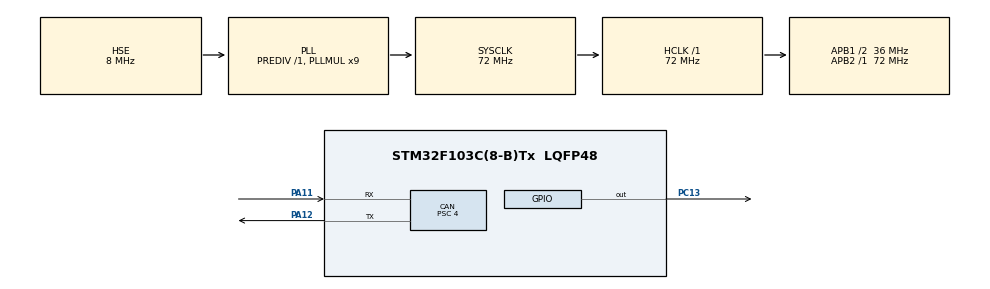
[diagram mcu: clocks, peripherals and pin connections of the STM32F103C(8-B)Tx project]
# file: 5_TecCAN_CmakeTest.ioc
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CAN.ABOM=ENABLE
CAN.BS1=CAN_BS1_14TQ
CAN.BS2=CAN_BS2_3TQ
CAN.CalculateBaudRate=500000
CAN.CalculateTimeBit=2000
CAN.CalculateTimeQuantum=111.11111111111111
CAN.Mode=CAN_MODE_NORMAL
CAN.NART=ENABLE
CAN.Prescaler=4
CAN.SJW=CAN_SJW_2TQ
CAN.TXFP=ENABLE
Mcu.Family=STM32F1
Mcu.Name=STM32F103C(8-B)Tx
Mcu.Package=LQFP48
NVIC.PriorityGroup=NVIC_PRIORITYGROUP_4
NVIC.USB_LP_CAN1_RX0_IRQn=true\:0\:0\:false\:false\:true\:true\:true\:true
PA11.Mode=CAN_Activate
PA11.Signal=CAN_RX
PA12.Mode=CAN_Activate
PA12.Signal=CAN_TX
PA13.Mode=Serial_Wire
PA13.Signal=SYS_JTMS-SWDIO
PA14.Mode=Serial_Wire
PA14.Signal=SYS_JTCK-SWCLK
PC13-TAMPER-RTC.PinState=GPIO_PIN_SET
PC13-TAMPER-RTC.Signal=GPIO_Output
PD0-OSC_IN.Mode=HSE-External-Oscillator
PD0-OSC_IN.Signal=RCC_OSC_IN
PD1-OSC_OUT.Mode=HSE-External-Oscillator
PD1-OSC_OUT.Signal=RCC_OSC_OUT
ProjectManager.HeapSize=0x200
ProjectManager.StackSize=0x800
ProjectManager.TargetToolchain=CMake
RCC.AHBFreq_Value=72000000
RCC.APB1CLKDivider=RCC_HCLK_DIV2
RCC.APB1Freq_Value=36000000
RCC.APB1TimFreq_Value=72000000
RCC.APB2Freq_Value=72000000
RCC.APB2TimFreq_Value=72000000
RCC.EnbaleCSS=true
RCC.HCLKFreq_Value=72000000
RCC.PLLMUL=RCC_PLL_MUL9
RCC.PLLSourceVirtual=RCC_PLLSOURCE_HSE
RCC.SYSCLKFreq_VALUE=72000000
RCC.SYSCLKSource=RCC_SYSCLKSOURCE_PLLCLK
RCC.USBFreq_Value=72000000
board=custom

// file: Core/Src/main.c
/* USER CODE BEGIN Header */
/**
  ******************************************************************************
  * @file           : main.c
  * @brief          : Main program body
  ******************************************************************************
  * @attention
  *
  * Copyright (c) 2025 STMicroelectronics.
  * All rights reserved.
  *
  * This software is licensed under terms that can be found in the LICENSE file
  * in the root directory of this software component.
  * If no LICENSE file comes with this software, it is provided AS-IS.
  *
  ******************************************************************************
  */
/* USER CODE END Header */
#include "main.h"
#include "can.h"
#include "gpio.h"

/* USER CODE BEGIN PV */

CAN_TxHeaderTypeDef TxHeader; // 发送句柄
CAN_RxHeaderTypeDef RxHeader; // 接收句柄
uint8_t TxData[8];
uint8_t RxData[8];
uint32_t TxMailbox;

/* USER CODE END PV */

void SystemClock_Config(void);

int main(void)
{

  /* MCU Configuration--------------------------------------------------------*/

  /* Reset of all peripherals, Initializes the Flash interface and the Systick. */
  HAL_Init();

  /* Configure the system clock */
  SystemClock_Config();

  /* Initialize all configured peripherals */
  MX_GPIO_Init();
  MX_CAN_Init();
  /* USER CODE BEGIN 2 */

  CAN_FilterTypeDef sFilterConfig;

sFilterConfig.FilterBank = 0;
sFilterConfig.FilterMode = CAN_FILTERMODE_IDMASK;
sFilterConfig.FilterScale = CAN_FILTERSCALE_32BIT;
sFilterConfig.FilterIdHigh = 0x0000;
sFilterConfig.FilterIdLow = 0x0000;
sFilterConfig.FilterMaskIdHigh = 0x0000;
sFilterConfig.FilterMaskIdLow = 0x0000; // 0表示允许所有ID通过
sFilterConfig.FilterFIFOAssignment = CAN_RX_FIFO0;
sFilterConfig.FilterActivation = ENABLE;
sFilterConfig.SlaveStartFilterBank = 0;

if (HAL_CAN_ConfigFilter(&hcan, &sFilterConfig) != HAL_OK) {
    Error_Handler();
}

HAL_CAN_Start(&hcan); // 启动CAN
HAL_CAN_ActivateNotification(&hcan, CAN_IT_RX_FIFO0_MSG_PENDING); // 开启中断通知

  /* USER CODE END 2 */

  /* Infinite loop */
  /* USER CODE BEGIN WHILE */

  TxHeader.StdId = 0x123;
TxHeader.RTR = CAN_RTR_DATA;
TxHeader.IDE = CAN_ID_STD;
TxHeader.DLC = 8;
TxData[0] = 0xAA; // 测试数据

  while (1)
  {
    if (HAL_CAN_GetTxMailboxesFreeLevel(&hcan) > 0)
    {
        HAL_CAN_AddTxMessage(&hcan, &TxHeader, TxData, &TxMailbox);
    }
    HAL_Delay(100);
    // HAL_CAN_AddTxMessage(&hcan, &TxHeader, TxData, &TxMailbox);
    // // HAL_GPIO_TogglePin(GPIOC, GPIO_PIN_13); // 翻转电平（用于观察）
    // HAL_Delay(500); // 每半秒发一次

    /* USER CODE END WHILE */

  }
}

void SystemClock_Config(void)
{
  RCC_OscInitTypeDef RCC_OscInitStruct = {0};
  RCC_ClkInitTypeDef RCC_ClkInitStruct = {0};

  /** Initializes the RCC Oscillators according to the specified parameters
  * in the RCC_OscInitTypeDef structure.
  */
  RCC_OscInitStruct.OscillatorType = RCC_OSCILLATORTYPE_HSE;
  RCC_OscInitStruct.HSEState = RCC_HSE_ON;
  RCC_OscInitStruct.HSEPredivValue = RCC_HSE_PREDIV_DIV1;
  RCC_OscInitStruct.HSIState = RCC_HSI_ON;
  RCC_OscInitStruct.PLL.PLLState = RCC_PLL_ON;
  RCC_OscInitStruct.PLL.PLLSource = RCC_PLLSOURCE_HSE;
  RCC_OscInitStruct.PLL.PLLMUL = RCC_PLL_MUL9;
  if (HAL_RCC_OscConfig(&RCC_OscInitStruct) != HAL_OK)
  {
    Error_Handler();
  }

  /** Initializes the CPU, AHB and APB buses clocks
  */
  RCC_ClkInitStruct.ClockType = RCC_CLOCKTYPE_HCLK|RCC_CLOCKTYPE_SYSCLK
                              |RCC_CLOCKTYPE_PCLK1|RCC_CLOCKTYPE_PCLK2;
  RCC_ClkInitStruct.SYSCLKSource = RCC_SYSCLKSOURCE_PLLCLK;
  RCC_ClkInitStruct.AHBCLKDivider = RCC_SYSCLK_DIV1;
  RCC_ClkInitStruct.APB1CLKDivider = RCC_HCLK_DIV2;
  RCC_ClkInitStruct.APB2CLKDivider = RCC_HCLK_DIV1;

  if (HAL_RCC_ClockConfig(&RCC_ClkInitStruct, FLASH_LATENCY_2) != HAL_OK)
  {
    Error_Handler();
  }

  /** Enables the Clock Security System
  */
  HAL_RCC_EnableCSS();
}

/* USER CODE BEGIN 4 */

void HAL_CAN_RxFifo0MsgPendingCallback(CAN_HandleTypeDef *hcan) {
    if (HAL_CAN_GetRxMessage(hcan, CAN_RX_FIFO0, &RxHeader, RxData) == HAL_OK) {
        // 如果接收到 ID 为 0x123 的消息，翻转电平（用于观察）
        // if (RxHeader.StdId == 0x123) {
        //     HAL_GPIO_TogglePin(GPIOC, GPIO_PIN_13);
        // }
        // 新增：如果接收到 ID 为 0x456 的消息，也翻转电平
        if (RxHeader.StdId == 0x456) {
            HAL_GPIO_TogglePin(GPIOC, GPIO_PIN_13);
        }
    }
}

/* USER CODE END 4 */

void Error_Handler(void)
{
  __disable_irq();
  while (1)
  {
  }
}
